AUTOSAR XML (schema 4-0-3)
standard types defined: Boolean, UInt16, UInt32, UInt8
package /AUTOSAR_Platform/DataConstrs
  range DC_Boolean: raw 0..1
  range DC_UInt16: raw 0..65535
  range DC_UInt8: raw 0..255
package /PATAC/MSM/ComponentTypes
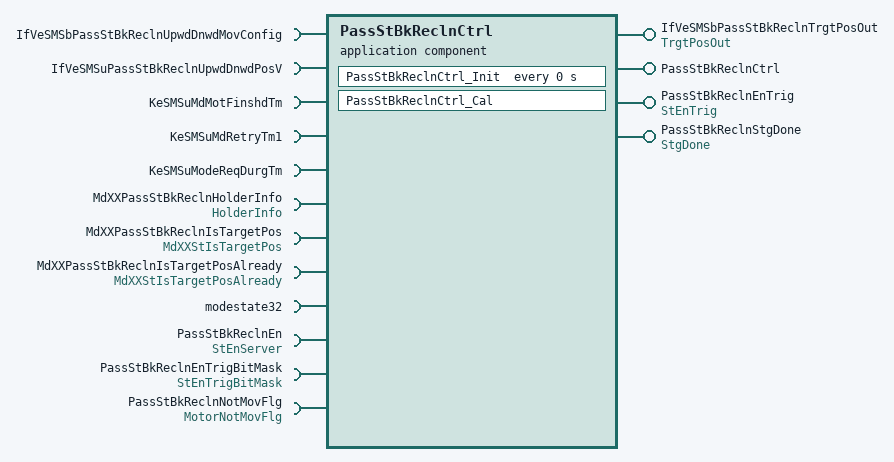
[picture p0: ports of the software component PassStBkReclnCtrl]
  application sw component type PassStBkReclnCtrl
    4 x provide port:
      IfVeSMSbPassStBkReclnTrgtPosOut: nonqueued-sender-com-spec{data-element=TrgtPosOut/Val, init-value=0}, provided-interface=TrgtPosOut
      PassStBkReclnCtrl: server-com-spec{operation=Cal, queue-length=1}, provided-interface=PassStBkReclnCtrl
      PassStBkReclnEnTrig: nonqueued-sender-com-spec{data-element=StEnTrig/Val, init-value=0}, provided-interface=StEnTrig
      PassStBkReclnStgDone: nonqueued-sender-com-spec{data-element=StgDone/Val, init-value=0}, provided-interface=StgDone
    12 x require port:
      IfVeSMSbPassStBkReclnUpwdDnwdMovConfig: nonqueued-receiver-com-spec{data-element=IfVeSMSbPassStBkReclnUpwdDnwdMovConfig/Val, filter=data-filter-type=ALWAYS, init-value=0}, required-interface=IfVeSMSbPassStBkReclnUpwdDnwdMovConfig
      IfVeSMSuPassStBkReclnUpwdDnwdPosV: nonqueued-receiver-com-spec{data-element=IfVeSMSuPassStBkReclnUpwdDnwdPosV/Val, filter=data-filter-type=ALWAYS, init-value=0}, required-interface=IfVeSMSuPassStBkReclnUpwdDnwdPosV
      KeSMSuMdMotFinshdTm: parameter-require-com-spec{init-value=0, parameter=KeSMSuMdMotFinshdTm/Val}, required-interface=KeSMSuMdMotFinshdTm
      KeSMSuMdRetryTm1: parameter-require-com-spec{init-value=0, parameter=KeSMSuMdRetryTm1/Val}, required-interface=KeSMSuMdRetryTm1
      KeSMSuModeReqDurgTm: parameter-require-com-spec{init-value=0, parameter=KeSMSuModeReqDurgTm/Val}, required-interface=KeSMSuModeReqDurgTm
      MdXXPassStBkReclnHolderInfo: nonqueued-receiver-com-spec{data-element=HolderInfo/Val, filter=data-filter-type=ALWAYS, init-value=0}, required-interface=HolderInfo
      MdXXPassStBkReclnIsTargetPos: nonqueued-receiver-com-spec{data-element=MdXXStIsTargetPos/Val, filter=data-filter-type=ALWAYS, init-value=0}, required-interface=MdXXStIsTargetPos
      MdXXPassStBkReclnIsTargetPosAlready: nonqueued-receiver-com-spec{data-element=MdXXStIsTargetPosAlready/Val, filter=data-filter-type=ALWAYS, init-value=0}, required-interface=MdXXStIsTargetPosAlready
      modestate32: nonqueued-receiver-com-spec{data-element=modestate32/Val, filter=data-filter-type=ALWAYS, init-value=0}, required-interface=modestate32
      PassStBkReclnEn: required-com-specs=[Clear, Get, Set], required-interface=StEnServer
      PassStBkReclnEnTrigBitMask: nonqueued-receiver-com-spec{data-element=StEnTrigBitMask/Val, filter=data-filter-type=ALWAYS, init-value=0}, required-interface=StEnTrigBitMask
      PassStBkReclnNotMovFlg: nonqueued-receiver-com-spec{data-element=MotorNotMovFlg/Val, filter=data-filter-type=ALWAYS, init-value=0}, required-interface=MotorNotMovFlg
    behavior PassStBkReclnCtrl_InternalBehavior
      operation invoked event OIT_PassStBkReclnCtrl_Cal_PassStBkReclnCtrl_Cal: start-on-event=PassStBkReclnCtrl_Cal, operation=PassStBkReclnCtrl.Cal
      timing event PassStBkReclnCtrl_InitEvent: start-on-event=PassStBkReclnCtrl_Init, period=0
      runnable PassStBkReclnCtrl_Cal
        data-receive-point-by-arguments:
          8 x access:
            REC_IfVeSMSbPassStBkReclnUpwdDnwdMovConfig_Val: accessed-variable=IfVeSMSbPassStBkReclnUpwdDnwdMovConfig.Val
            REC_IfVeSMSuPassStBkReclnUpwdDnwdPosV_Val: accessed-variable=IfVeSMSuPassStBkReclnUpwdDnwdPosV.Val
            REC_MdXXPassStBkReclnHolderInfo_Val: accessed-variable=MdXXPassStBkReclnHolderInfo.Val
            REC_MdXXPassStBkReclnIsTargetPos_Val: accessed-variable=MdXXPassStBkReclnIsTargetPos.Val
            REC_MdXXPassStBkReclnIsTargetPosAlready_Val: accessed-variable=MdXXPassStBkReclnIsTargetPosAlready.Val
            REC_modestate32_Val: accessed-variable=modestate32.Val
            REC_PassStBkReclnEnTrigBitMask_Val: accessed-variable=PassStBkReclnEnTrigBitMask.Val
            REC_PassStBkReclnNotMovFlg_Val: accessed-variable=PassStBkReclnNotMovFlg.Val
        data-send-points:
          access SEND_IfVeSMSbPassStBkReclnTrgtPosOut_Val: accessed-variable=IfVeSMSbPassStBkReclnTrgtPosOut.Val
          access SEND_PassStBkReclnEnTrig_Val: accessed-variable=PassStBkReclnEnTrig.Val
          access SEND_PassStBkReclnStgDone_Val: accessed-variable=PassStBkReclnStgDone.Val
        parameter access PA_KeSMSuMdMotFinshdTm_Val: accessed-parameter=KeSMSuMdMotFinshdTm.Val
        parameter access PA_KeSMSuMdRetryTm1_Val: accessed-parameter=KeSMSuMdRetryTm1.Val
        parameter access PA_KeSMSuModeReqDurgTm_Val: accessed-parameter=KeSMSuModeReqDurgTm.Val
        sync call SC_PassStBkReclnEn_Get: operation=PassStBkReclnEn.Get, timeout=0
      runnable PassStBkReclnCtrl_Init
        parameter access PA_KeSMSuMdMotFinshdTm_Val: accessed-parameter=KeSMSuMdMotFinshdTm.Val
        parameter access PA_KeSMSuMdRetryTm1_Val: accessed-parameter=KeSMSuMdRetryTm1.Val
        parameter access PA_KeSMSuModeReqDurgTm_Val: accessed-parameter=KeSMSuModeReqDurgTm.Val
  swc implementation PassStBkReclnCtrl_Implementation: behavior=PassStBkReclnCtrl_InternalBehavior
    code-descriptors:
      code Default: artifact-descriptors=autosar-engineering-object={short-label=Default, category=SWSRC}
package /PATAC/MSM/ModeAdjust/CalPortInterface
  parameter interface KeSMSuMdMotFinshdTm
    parameter data prototype Val: sw-calibration-access=READ-WRITE, type=UInt16
  parameter interface KeSMSuModeReqDurgTm
    parameter data prototype Val: sw-calibration-access=READ-WRITE, type=UInt16
package /PATAC/MSM/ModeAdjust/Interfaces
  sender receiver interface IfVeSMSuPassStBkReclnUpwdDnwdPosV: invalidation-policy{data-element=IfVeSMSuPassStBkReclnUpwdDnwdPosV/Val, handle-invalid=DONT-INVALIDATE}
    data Val: type=Boolean
package /PATAC/MSM/ModeAdjust/PortInterface
  client server interface PassStBkReclnCtrl
    operation Cal
  client server interface StEnServer
    operation Clear
      arg data: type=UInt8, direction=IN, server-argument-impl-policy=USE-ARGUMENT-TYPE
    operation Get
      arg data: type=UInt32, direction=OUT, server-argument-impl-policy=USE-ARGUMENT-TYPE
    operation Set
      arg data: type=UInt8, direction=IN, server-argument-impl-policy=USE-ARGUMENT-TYPE
  9 x sender receiver interface:
    HolderInfo: invalidation-policy{data-element=HolderInfo/Val, handle-invalid=DONT-INVALIDATE}
      data Val: type=UInt32
    MdXXStIsTargetPos: invalidation-policy{data-element=MdXXStIsTargetPos/Val, handle-invalid=DONT-INVALIDATE}
      data Val: type=UInt32
    MdXXStIsTargetPosAlready: invalidation-policy{data-element=MdXXStIsTargetPosAlready/Val, handle-invalid=DONT-INVALIDATE}
      data Val: type=UInt32
    modestate32: invalidation-policy{data-element=modestate32/Val, handle-invalid=DONT-INVALIDATE}
      data Val: type=UInt32
    MotorNotMovFlg: invalidation-policy{data-element=MotorNotMovFlg/Val, handle-invalid=DONT-INVALIDATE}
      data Val: type=Boolean
    StEnTrig: invalidation-policy{data-element=StEnTrig/Val, handle-invalid=DONT-INVALIDATE}
      data Val: type=Boolean
    StEnTrigBitMask: invalidation-policy{data-element=StEnTrigBitMask/Val, handle-invalid=DONT-INVALIDATE}
      data Val: type=UInt32
    StgDone: invalidation-policy{data-element=StgDone/Val, handle-invalid=DONT-INVALIDATE}
      data Val: type=Boolean
    TrgtPosOut: invalidation-policy{data-element=TrgtPosOut/Val, handle-invalid=DONT-INVALIDATE}
      data Val: type=Boolean
package /PATAC/MSM/PortInterfaces
  parameter interface KeSMSuMdRetryTm1
    parameter data prototype Val: sw-calibration-access=READ-WRITE, type=UInt8
  sender receiver interface IfVeSMSbPassStBkReclnUpwdDnwdMovConfig: invalidation-policy{data-element=IfVeSMSbPassStBkReclnUpwdDnwdMovConfig/Val, handle-invalid=DONT-INVALIDATE}
    data Val: type=Boolean
